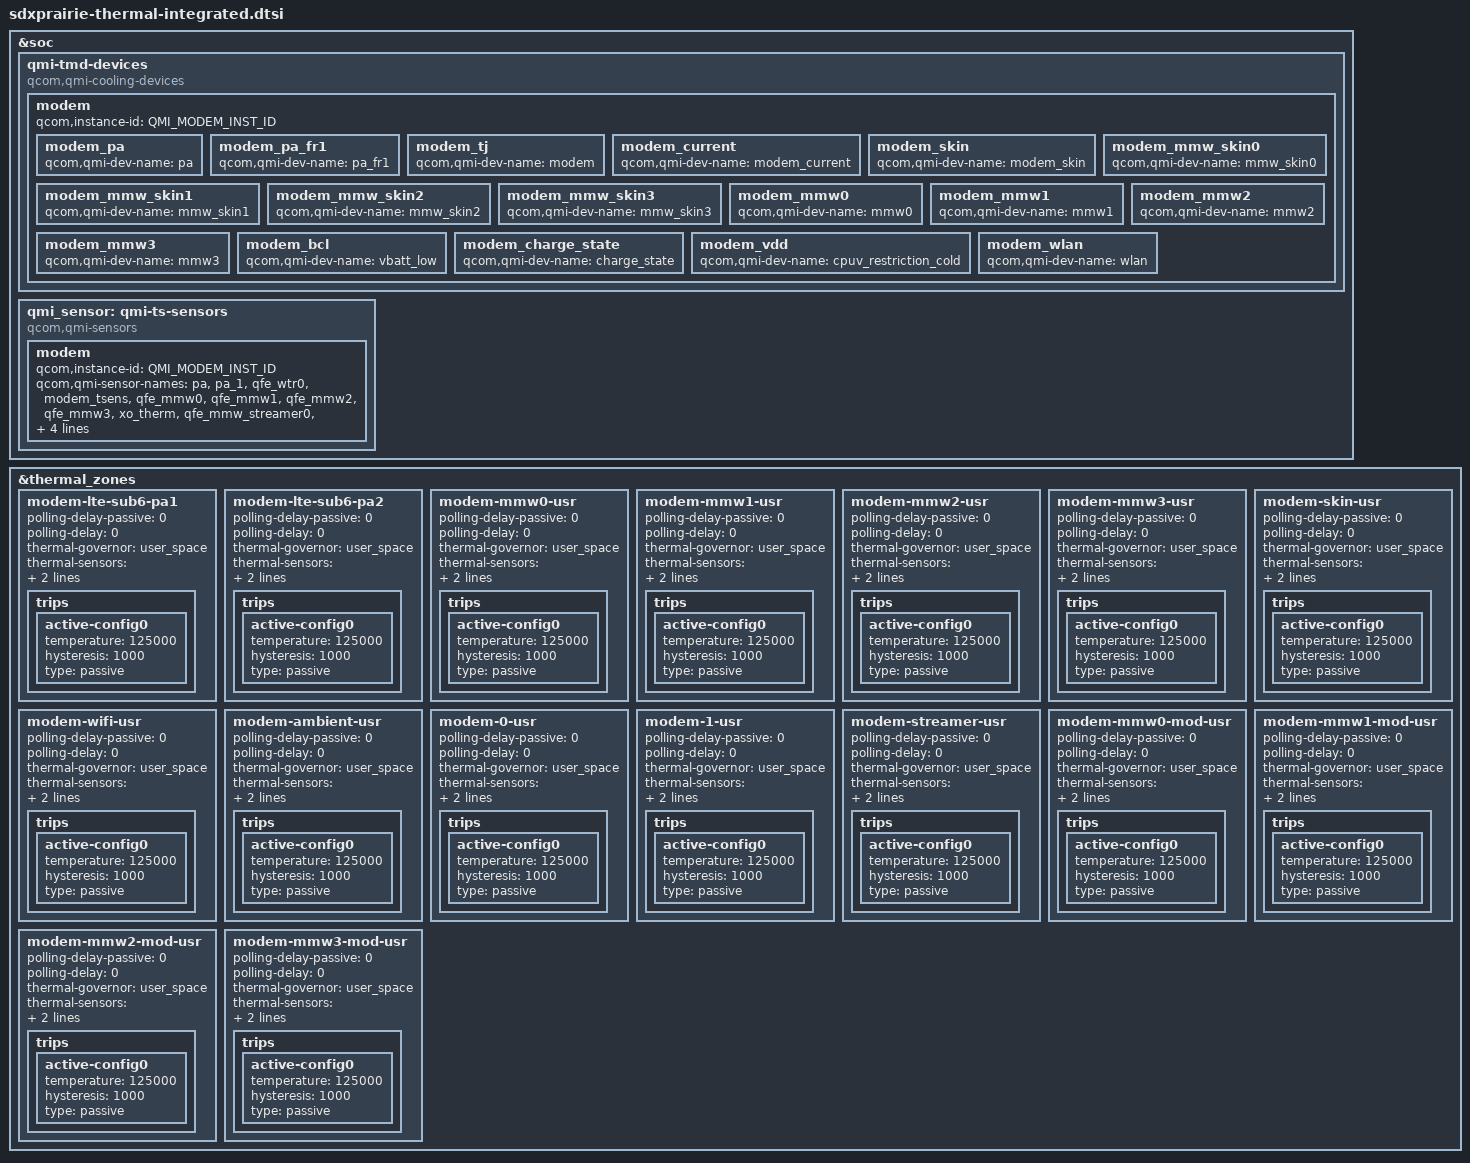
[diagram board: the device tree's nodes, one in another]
#include <dt-bindings/thermal/qmi_thermal.h>

&soc {
	qmi-tmd-devices {
		compatible = "qcom,qmi-cooling-devices";

		modem {
			qcom,instance-id = <QMI_MODEM_INST_ID>;

			modem_pa: modem_pa {
				qcom,qmi-dev-name = "pa";
				#cooling-cells = <2>;
			};

			modem_pa_fr1: modem_pa_fr1 {
				qcom,qmi-dev-name = "pa_fr1";
				#cooling-cells = <2>;
			};

			modem_tj: modem_tj {
				qcom,qmi-dev-name = "modem";
				#cooling-cells = <2>;
			};

			modem_current: modem_current {
				qcom,qmi-dev-name = "modem_current";
				#cooling-cells = <2>;
			};

			modem_skin: modem_skin {
				qcom,qmi-dev-name = "modem_skin";
				#cooling-cells = <2>;
			};

			modem_mmw_skin0: modem_mmw_skin0 {
				qcom,qmi-dev-name = "mmw_skin0";
				#cooling-cells = <2>;
			};

			modem_mmw_skin1: modem_mmw_skin1 {
				qcom,qmi-dev-name = "mmw_skin1";
				#cooling-cells = <2>;
			};

			modem_mmw_skin2: modem_mmw_skin2 {
				qcom,qmi-dev-name = "mmw_skin2";
				#cooling-cells = <2>;
			};

			modem_mmw_skin3: modem_mmw_skin3 {
				qcom,qmi-dev-name = "mmw_skin3";
				#cooling-cells = <2>;
			};

			modem_mmw0: modem_mmw0 {
				qcom,qmi-dev-name = "mmw0";
				#cooling-cells = <2>;
			};

			modem_mmw1: modem_mmw1 {
				qcom,qmi-dev-name = "mmw1";
				#cooling-cells = <2>;
			};

			modem_mmw2: modem_mmw2 {
				qcom,qmi-dev-name = "mmw2";
				#cooling-cells = <2>;
			};

			modem_mmw3: modem_mmw3 {
				qcom,qmi-dev-name = "mmw3";
				#cooling-cells = <2>;
			};

			modem_bcl: modem_bcl {
				qcom,qmi-dev-name = "vbatt_low";
				#cooling-cells = <2>;
			};

			modem_charge_state: modem_charge_state {
				qcom,qmi-dev-name = "charge_state";
				#cooling-cells = <2>;
			};

			modem_vdd: modem_vdd {
				qcom,qmi-dev-name = "cpuv_restriction_cold";
				#cooling-cells = <2>;
			};

			modem_wlan: modem_wlan {
				qcom,qmi-dev-name = "wlan";
				#cooling-cells = <2>;
			};
		};
	};

	qmi_sensor: qmi-ts-sensors {
		compatible = "qcom,qmi-sensors";
		#thermal-sensor-cells = <1>;

		modem {
			qcom,instance-id = <QMI_MODEM_INST_ID>;
			qcom,qmi-sensor-names = "pa",
						"pa_1",
						"qfe_wtr0",
						"modem_tsens",
						"qfe_mmw0",
						"qfe_mmw1",
						"qfe_mmw2",
						"qfe_mmw3",
						"xo_therm",
						"qfe_mmw_streamer0",
						"qfe_mmw0_mod",
						"qfe_mmw1_mod",
						"qfe_mmw2_mod",
						"qfe_mmw3_mod",
						"qfe_ret_pa0",
						"qfe_wtr_pa0",
						"qfe_wtr_pa1",
						"qfe_wtr_pa2",
						"qfe_wtr_pa3",
						"sys_therm1",
						"sys_therm2",
						"modem_tsens1";
		};
	};
};

&thermal_zones {
	modem-lte-sub6-pa1 {
		polling-delay-passive = <0>;
		polling-delay = <0>;
		thermal-governor = "user_space";
		thermal-sensors = <&qmi_sensor
				(QMI_MODEM_INST_ID+QMI_PA)>;
		wake-capable-sensor;
		trips {
			active-config0 {
				temperature = <125000>;
				hysteresis = <1000>;
				type = "passive";
			};
		};
	};

	modem-lte-sub6-pa2 {
		polling-delay-passive = <0>;
		polling-delay = <0>;
		thermal-governor = "user_space";
		thermal-sensors = <&qmi_sensor
				(QMI_MODEM_INST_ID+QMI_PA_1)>;
		wake-capable-sensor;
		trips {
			active-config0 {
				temperature = <125000>;
				hysteresis = <1000>;
				type = "passive";
			};
		};
	};

	modem-mmw0-usr {
		polling-delay-passive = <0>;
		polling-delay = <0>;
		thermal-governor = "user_space";
		thermal-sensors = <&qmi_sensor
				(QMI_MODEM_INST_ID+QMI_QFE_MMW_0)>;
		wake-capable-sensor;
		trips {
			active-config0 {
				temperature = <125000>;
				hysteresis = <1000>;
				type = "passive";
			};
		};
	};

	modem-mmw1-usr {
		polling-delay-passive = <0>;
		polling-delay = <0>;
		thermal-governor = "user_space";
		thermal-sensors = <&qmi_sensor
				(QMI_MODEM_INST_ID+QMI_QFE_MMW_1)>;
		wake-capable-sensor;
		trips {
			active-config0 {
				temperature = <125000>;
				hysteresis = <1000>;
				type = "passive";
			};
		};
	};

	modem-mmw2-usr {
		polling-delay-passive = <0>;
		polling-delay = <0>;
		thermal-governor = "user_space";
		thermal-sensors = <&qmi_sensor
				(QMI_MODEM_INST_ID+QMI_QFE_MMW_2)>;
		wake-capable-sensor;
		trips {
			active-config0 {
				temperature = <125000>;
				hysteresis = <1000>;
				type = "passive";
			};
		};
	};

	modem-mmw3-usr {
		polling-delay-passive = <0>;
		polling-delay = <0>;
		thermal-governor = "user_space";
		thermal-sensors = <&qmi_sensor
				(QMI_MODEM_INST_ID+QMI_QFE_MMW_3)>;
		wake-capable-sensor;
		trips {
			active-config0 {
				temperature = <125000>;
				hysteresis = <1000>;
				type = "passive";
			};
		};
	};

	modem-skin-usr {
		polling-delay-passive = <0>;
		polling-delay = <0>;
		thermal-governor = "user_space";
		thermal-sensors = <&qmi_sensor
				(QMI_MODEM_INST_ID+QMI_XO_THERM)>;
		wake-capable-sensor;
		trips {
			active-config0 {
				temperature = <125000>;
				hysteresis = <1000>;
				type = "passive";
			};
		};
	};

	modem-wifi-usr {
		polling-delay-passive = <0>;
		polling-delay = <0>;
		thermal-governor = "user_space";
		thermal-sensors = <&qmi_sensor
				(QMI_MODEM_INST_ID+QMI_SYS_THERM_1)>;
		wake-capable-sensor;
		trips {
			active-config0 {
				temperature = <125000>;
				hysteresis = <1000>;
				type = "passive";
			};
		};
	};

	modem-ambient-usr {
		polling-delay-passive = <0>;
		polling-delay = <0>;
		thermal-governor = "user_space";
		thermal-sensors = <&qmi_sensor
				(QMI_MODEM_INST_ID+QMI_SYS_THERM_2)>;
		wake-capable-sensor;
		trips {
			active-config0 {
				temperature = <125000>;
				hysteresis = <1000>;
				type = "passive";
			};
		};
	};

	modem-0-usr {
		polling-delay-passive = <0>;
		polling-delay = <0>;
		thermal-governor = "user_space";
		thermal-sensors = <&qmi_sensor
				(QMI_MODEM_INST_ID+QMI_MODEM_TSENS)>;
		wake-capable-sensor;
		trips {
			active-config0 {
				temperature = <125000>;
				hysteresis = <1000>;
				type = "passive";
			};
		};
	};

	modem-1-usr {
		polling-delay-passive = <0>;
		polling-delay = <0>;
		thermal-governor = "user_space";
		thermal-sensors = <&qmi_sensor
				(QMI_MODEM_INST_ID+QMI_MODEM_TSENS_1)>;
		wake-capable-sensor;
		trips {
			active-config0 {
				temperature = <125000>;
				hysteresis = <1000>;
				type = "passive";
			};
		};
	};

	modem-streamer-usr {
		polling-delay-passive = <0>;
		polling-delay = <0>;
		thermal-governor = "user_space";
		thermal-sensors = <&qmi_sensor
				(QMI_MODEM_INST_ID+QMI_QFE_MMW_STREAMER_0)>;
		wake-capable-sensor;
		trips {
			active-config0 {
				temperature = <125000>;
				hysteresis = <1000>;
				type = "passive";
			};
		};
	};

	modem-mmw0-mod-usr {
		polling-delay-passive = <0>;
		polling-delay = <0>;
		thermal-governor = "user_space";
		thermal-sensors = <&qmi_sensor
				(QMI_MODEM_INST_ID+QMI_QFE_MMW_0_MOD)>;
		wake-capable-sensor;
		trips {
			active-config0 {
				temperature = <125000>;
				hysteresis = <1000>;
				type = "passive";
			};
		};
	};

	modem-mmw1-mod-usr {
		polling-delay-passive = <0>;
		polling-delay = <0>;
		thermal-governor = "user_space";
		thermal-sensors = <&qmi_sensor
				(QMI_MODEM_INST_ID+QMI_QFE_MMW_1_MOD)>;
		wake-capable-sensor;
		trips {
			active-config0 {
				temperature = <125000>;
				hysteresis = <1000>;
				type = "passive";
			};
		};
	};

	modem-mmw2-mod-usr {
		polling-delay-passive = <0>;
		polling-delay = <0>;
		thermal-governor = "user_space";
		thermal-sensors = <&qmi_sensor
				(QMI_MODEM_INST_ID+QMI_QFE_MMW_2_MOD)>;
		wake-capable-sensor;
		trips {
			active-config0 {
				temperature = <125000>;
				hysteresis = <1000>;
				type = "passive";
			};
		};
	};

	modem-mmw3-mod-usr {
		polling-delay-passive = <0>;
		polling-delay = <0>;
		thermal-governor = "user_space";
		thermal-sensors = <&qmi_sensor
				(QMI_MODEM_INST_ID+QMI_QFE_MMW_3_MOD)>;
		wake-capable-sensor;
		trips {
			active-config0 {
				temperature = <125000>;
				hysteresis = <1000>;
				type = "passive";
			};
		};
	};
};
